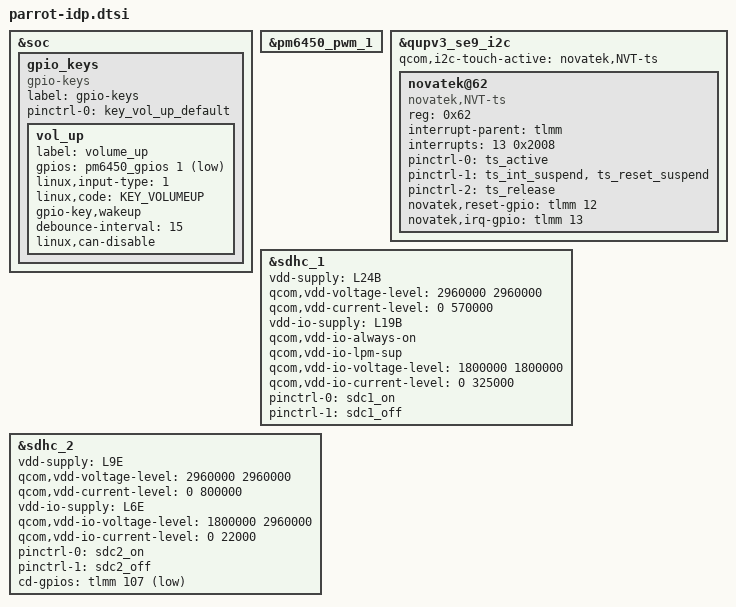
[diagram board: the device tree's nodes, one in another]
#include <dt-bindings/gpio/gpio.h>
#include <dt-bindings/input/input.h>

#include "parrot-pmic-overlay.dtsi"
#include "parrot-thermal-overlay.dtsi"

&soc {
	gpio_keys {
		compatible = "gpio-keys";
		label = "gpio-keys";

		pinctrl-names = "default";
		pinctrl-0 = <&key_vol_up_default>;

		vol_up {
			label = "volume_up";
			gpios = <&pm6450_gpios 1 GPIO_ACTIVE_LOW>;
			linux,input-type = <1>;
			linux,code = <KEY_VOLUMEUP>;
			gpio-key,wakeup;
			debounce-interval = <15>;
			linux,can-disable;
		};
	};
};

&pm6450_pwm_1 {
	status = "ok";
};

&qupv3_se9_i2c {
	#address-cells = <1>;
	#size-cells = <0>;

	status = "ok";
	qcom,i2c-touch-active = "novatek,NVT-ts";

	novatek@62 {
		compatible = "novatek,NVT-ts";
		reg = <0x62>;

		interrupt-parent = <&tlmm>;
		interrupts = <13 0x2008>;

		pinctrl-names = "pmx_ts_active","pmx_ts_suspend",
			"pmx_ts_release";

		pinctrl-0 = <&ts_active>;
		pinctrl-1 = <&ts_int_suspend &ts_reset_suspend>;
		pinctrl-2 = <&ts_release>;

		novatek,reset-gpio = <&tlmm 12 0x00>;
		novatek,irq-gpio = <&tlmm 13 0x2008>;
	};
};

&sdhc_1 {
	status = "ok";

	vdd-supply = <&L24B>;
	qcom,vdd-voltage-level = <2960000 2960000>;
	qcom,vdd-current-level = <0 570000>;

	vdd-io-supply = <&L19B>;
	qcom,vdd-io-always-on;
	qcom,vdd-io-lpm-sup;
	qcom,vdd-io-voltage-level = <1800000 1800000>;
	qcom,vdd-io-current-level = <0 325000>;

	pinctrl-names = "default", "sleep";
	pinctrl-0 = <&sdc1_on>;
	pinctrl-1 = <&sdc1_off>;
};

&sdhc_2 {
	status = "ok";

	vdd-supply = <&L9E>;
	qcom,vdd-voltage-level = <2960000 2960000>;
	qcom,vdd-current-level = <0 800000>;

	vdd-io-supply = <&L6E>;
	qcom,vdd-io-voltage-level = <1800000 2960000>;
	qcom,vdd-io-current-level = <0 22000>;

	pinctrl-names = "default", "sleep";
	pinctrl-0 = <&sdc2_on>;
	pinctrl-1 = <&sdc2_off>;

	cd-gpios = <&tlmm 107 GPIO_ACTIVE_LOW>;
};
